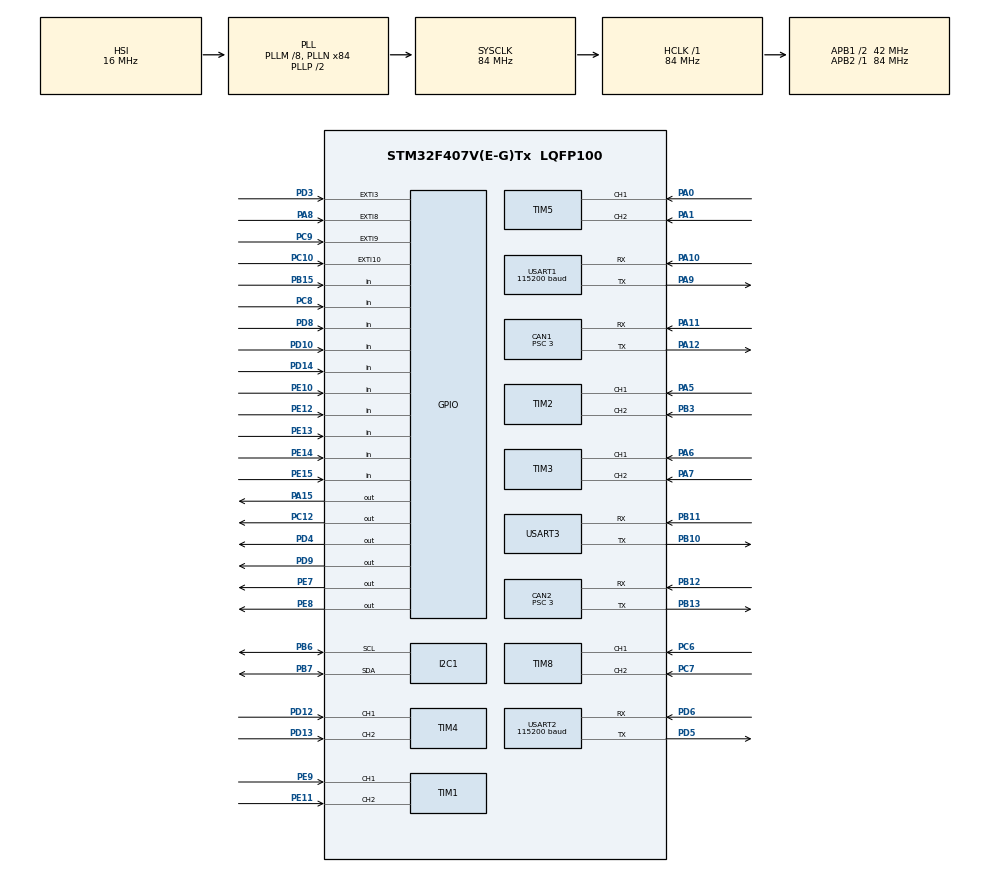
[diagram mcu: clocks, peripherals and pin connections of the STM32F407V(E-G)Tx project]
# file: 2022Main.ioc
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CAN1.ABOM=ENABLE
CAN1.BS1=CAN_BS1_11TQ
CAN1.BS2=CAN_BS2_2TQ
CAN1.CalculateBaudRate=1000000
CAN1.CalculateTimeBit=1000
CAN1.CalculateTimeQuantum=71.42857142857143
CAN1.NART=ENABLE
CAN1.Prescaler=3
CAN1.TXFP=ENABLE
CAN2.ABOM=ENABLE
CAN2.BS1=CAN_BS1_11TQ
CAN2.BS2=CAN_BS2_2TQ
CAN2.CalculateBaudRate=1000000
CAN2.CalculateTimeBit=1000
CAN2.CalculateTimeQuantum=71.42857142857143
CAN2.NART=ENABLE
CAN2.Prescaler=3
CAN2.TXFP=ENABLE
Mcu.Family=STM32F4
Mcu.Name=STM32F407V(E-G)Tx
Mcu.Package=LQFP100
NVIC.CAN1_RX0_IRQn=true\:0\:0\:false\:false\:true\:true\:true\:true
NVIC.CAN2_RX0_IRQn=true\:1\:0\:true\:false\:true\:true\:true\:true
NVIC.EXTI15_10_IRQn=true\:0\:0\:false\:false\:true\:true\:true\:true
NVIC.EXTI3_IRQn=true\:0\:0\:false\:false\:true\:true\:true\:true
NVIC.EXTI9_5_IRQn=true\:0\:0\:false\:false\:true\:true\:true\:true
NVIC.PriorityGroup=NVIC_PRIORITYGROUP_4
NVIC.TIM6_DAC_IRQn=true\:0\:0\:false\:false\:true\:true\:true\:true
NVIC.USART1_IRQn=true\:0\:0\:false\:false\:true\:true\:true\:true
PA0-WKUP.Signal=S_TIM5_CH1
PA1.Signal=S_TIM5_CH2
PA10.Mode=Asynchronous
PA10.Signal=USART1_RX
PA11.Mode=CAN_Activate
PA11.Signal=CAN1_RX
PA12.Mode=CAN_Activate
PA12.Signal=CAN1_TX
PA13.Mode=Serial_Wire
PA13.Signal=SYS_JTMS-SWDIO
PA14.Mode=Serial_Wire
PA14.Signal=SYS_JTCK-SWCLK
PA15.Signal=GPIO_Output
PA5.Signal=S_TIM2_CH1_ETR
PA6.Signal=S_TIM3_CH1
PA7.Signal=S_TIM3_CH2
PA8.GPIO_ModeDefaultEXTI=GPIO_MODE_IT_FALLING
PA8.Signal=GPXTI8
PA9.Mode=Asynchronous
PA9.Signal=USART1_TX
PB10.Mode=Asynchronous
PB10.Signal=USART3_TX
PB11.Mode=Asynchronous
PB11.Signal=USART3_RX
PB12.Mode=CAN_Activate
PB12.Signal=CAN2_RX
PB13.Mode=CAN_Activate
PB13.Signal=CAN2_TX
PB15.Signal=GPIO_Input
PB3.Signal=S_TIM2_CH2
PB6.GPIO_Pu=GPIO_PULLUP
PB6.Mode=I2C
PB6.Signal=I2C1_SCL
PB7.GPIO_Pu=GPIO_PULLUP
PB7.Mode=I2C
PB7.Signal=I2C1_SDA
PC10.GPIO_ModeDefaultEXTI=GPIO_MODE_IT_RISING_FALLING
PC10.Signal=GPXTI10
PC12.GPIO_PuPd=GPIO_PULLDOWN
PC12.Signal=GPIO_Output
PC6.Signal=S_TIM8_CH1
PC7.Signal=S_TIM8_CH2
PC8.Signal=GPIO_Input
PC9.GPIO_ModeDefaultEXTI=GPIO_MODE_IT_RISING
PC9.Signal=GPXTI9
PD10.Signal=GPIO_Input
PD12.Signal=S_TIM4_CH1
PD13.Signal=S_TIM4_CH2
PD14.Signal=GPIO_Input
PD3.GPIO_ModeDefaultEXTI=GPIO_MODE_IT_RISING_FALLING
PD3.Signal=GPXTI3
PD4.Signal=GPIO_Output
PD5.Mode=Asynchronous
PD5.Signal=USART2_TX
PD6.Mode=Asynchronous
PD6.Signal=USART2_RX
PD8.Signal=GPIO_Input
PD9.Signal=GPIO_Output
PE10.Signal=GPIO_Input
PE11.Signal=S_TIM1_CH2
PE12.Signal=GPIO_Input
PE13.Signal=GPIO_Input
PE14.Signal=GPIO_Input
PE15.Signal=GPIO_Input
PE7.Signal=GPIO_Output
PE8.Signal=GPIO_Output
PE9.Signal=S_TIM1_CH1
ProjectManager.HeapSize=0x200
ProjectManager.StackSize=0x400
ProjectManager.TargetToolchain=STM32CubeIDE
RCC.48MHZClocksFreq_Value=42000000
RCC.AHBFreq_Value=84000000
RCC.APB1CLKDivider=RCC_HCLK_DIV2
RCC.APB1Freq_Value=42000000
RCC.APB1TimFreq_Value=84000000
RCC.APB2Freq_Value=84000000
RCC.APB2TimFreq_Value=84000000
RCC.CortexFreq_Value=84000000
RCC.HCLKFreq_Value=84000000
RCC.HSE_VALUE=25000000
RCC.HSI_VALUE=16000000
RCC.LSE_VALUE=32768
RCC.PLLM=8
RCC.PLLN=84
RCC.SYSCLKFreq_VALUE=84000000
RCC.SYSCLKSource=RCC_SYSCLKSOURCE_PLLCLK
RCC.VCOOutputFreq_Value=168000000
SH.S_TIM1_CH1.0=TIM1_CH1,Encoder_Interface
SH.S_TIM1_CH2.0=TIM1_CH2,Encoder_Interface
SH.S_TIM2_CH1_ETR.0=TIM2_CH1,Encoder_Interface
SH.S_TIM2_CH2.0=TIM2_CH2,Encoder_Interface
SH.S_TIM3_CH1.0=TIM3_CH1,Encoder_Interface
SH.S_TIM3_CH2.0=TIM3_CH2,Encoder_Interface
SH.S_TIM4_CH1.0=TIM4_CH1,Encoder_Interface
SH.S_TIM4_CH2.0=TIM4_CH2,Encoder_Interface
SH.S_TIM5_CH1.0=TIM5_CH1,Encoder_Interface
SH.S_TIM5_CH2.0=TIM5_CH2,Encoder_Interface
SH.S_TIM8_CH1.0=TIM8_CH1,Encoder_Interface
SH.S_TIM8_CH2.0=TIM8_CH2,Encoder_Interface
TIM1.AutoReloadPreload=TIM_AUTORELOAD_PRELOAD_ENABLE
TIM1.EncoderMode=TIM_ENCODERMODE_TI12
TIM2.AutoReloadPreload=TIM_AUTORELOAD_PRELOAD_ENABLE
TIM2.EncoderMode=TIM_ENCODERMODE_TI12
TIM3.AutoReloadPreload=TIM_AUTORELOAD_PRELOAD_ENABLE
TIM3.CounterMode=TIM_COUNTERMODE_UP
TIM3.EncoderMode=TIM_ENCODERMODE_TI12
TIM4.AutoReloadPreload=TIM_AUTORELOAD_PRELOAD_ENABLE
TIM4.EncoderMode=TIM_ENCODERMODE_TI12
TIM5.AutoReloadPreload=TIM_AUTORELOAD_PRELOAD_ENABLE
TIM5.EncoderMode=TIM_ENCODERMODE_TI12
TIM6.AutoReloadPreload=TIM_AUTORELOAD_PRELOAD_ENABLE
TIM6.Period=8399
TIM6.Prescaler=99
TIM8.AutoReloadPreload=TIM_AUTORELOAD_PRELOAD_ENABLE
TIM8.EncoderMode=TIM_ENCODERMODE_TI12
USART1.BaudRate=115200
USART1.Mode=MODE_TX
USART1.VirtualMode=VM_ASYNC
USART2.BaudRate=115200
USART2.VirtualMode=VM_ASYNC
USART3.VirtualMode=VM_ASYNC
VP_TIM6_VS_ClockSourceINT.Mode=Enable_Timer
board=custom

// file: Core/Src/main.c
/* USER CODE BEGIN Header */
/**
  ******************************************************************************
  * @file           : main.c
  * @brief          : Main program body
  ******************************************************************************
  * @attention
  *
  * Copyright (c) 2022 STMicroelectronics.
  * All rights reserved.
  *
  * This software is licensed under terms that can be found in the LICENSE file
  * in the root directory of this software component.
  * If no LICENSE file comes with this software, it is provided AS-IS.
  *
  ******************************************************************************
  */
/* USER CODE END Header */
#include "main.h"
#include "can.h"
#include "i2c.h"
#include "tim.h"
#include "usart.h"
#include "gpio.h"

/* USER CODE BEGIN Includes */
#include "mainpp.h"
/* USER CODE END Includes */

void SystemClock_Config(void);

int main(void)
{

  /* MCU Configuration--------------------------------------------------------*/

  /* Reset of all peripherals, Initializes the Flash interface and the Systick. */
  HAL_Init();

  /* Configure the system clock */
  SystemClock_Config();

  /* Initialize all configured peripherals */
  MX_GPIO_Init();
  MX_USART1_UART_Init();
  MX_TIM2_Init();
  MX_CAN1_Init();
  MX_I2C1_Init();
  MX_TIM1_Init();
  MX_TIM3_Init();
  MX_TIM4_Init();
  MX_TIM5_Init();
  MX_USART2_UART_Init();
  MX_USART3_UART_Init();
  MX_TIM8_Init();
  MX_TIM6_Init();
  MX_CAN2_Init();
  /* USER CODE BEGIN 2 */
  mainpp();
  /* USER CODE END 2 */

  /* Infinite loop */
  while (1)
  {

  }
}

void SystemClock_Config(void)
{
  RCC_OscInitTypeDef RCC_OscInitStruct = {0};
  RCC_ClkInitTypeDef RCC_ClkInitStruct = {0};

  /** Configure the main internal regulator output voltage
  */
  __HAL_RCC_PWR_CLK_ENABLE();
  __HAL_PWR_VOLTAGESCALING_CONFIG(PWR_REGULATOR_VOLTAGE_SCALE1);

  /** Initializes the RCC Oscillators according to the specified parameters
  * in the RCC_OscInitTypeDef structure.
  */
  RCC_OscInitStruct.OscillatorType = RCC_OSCILLATORTYPE_HSI;
  RCC_OscInitStruct.HSIState = RCC_HSI_ON;
  RCC_OscInitStruct.HSICalibrationValue = RCC_HSICALIBRATION_DEFAULT;
  RCC_OscInitStruct.PLL.PLLState = RCC_PLL_ON;
  RCC_OscInitStruct.PLL.PLLSource = RCC_PLLSOURCE_HSI;
  RCC_OscInitStruct.PLL.PLLM = 8;
  RCC_OscInitStruct.PLL.PLLN = 84;
  RCC_OscInitStruct.PLL.PLLP = RCC_PLLP_DIV2;
  RCC_OscInitStruct.PLL.PLLQ = 4;
  if (HAL_RCC_OscConfig(&RCC_OscInitStruct) != HAL_OK)
  {
    Error_Handler();
  }

  /** Initializes the CPU, AHB and APB buses clocks
  */
  RCC_ClkInitStruct.ClockType = RCC_CLOCKTYPE_HCLK|RCC_CLOCKTYPE_SYSCLK
                              |RCC_CLOCKTYPE_PCLK1|RCC_CLOCKTYPE_PCLK2;
  RCC_ClkInitStruct.SYSCLKSource = RCC_SYSCLKSOURCE_PLLCLK;
  RCC_ClkInitStruct.AHBCLKDivider = RCC_SYSCLK_DIV1;
  RCC_ClkInitStruct.APB1CLKDivider = RCC_HCLK_DIV2;
  RCC_ClkInitStruct.APB2CLKDivider = RCC_HCLK_DIV1;

  if (HAL_RCC_ClockConfig(&RCC_ClkInitStruct, FLASH_LATENCY_2) != HAL_OK)
  {
    Error_Handler();
  }
}

void Error_Handler(void)
{
  __disable_irq();
  while (1)
  {
  }
}
